# GD32E511_512 register map
File version: 1.0
CPU: CM33 r0p4, little endian, MPU, FPU, 4 interrupt priority bits
Registers are 32-bit, read-write, reset 0x0 unless marked. A register's access mark holds for its fields unless they carry their own. Offsets are from the block's base; [hi:lo] are bit positions.

## MDIO — Management data input/output
Base 0x4000D800
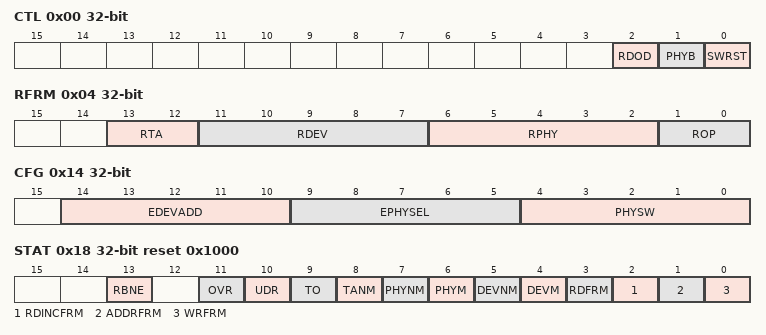
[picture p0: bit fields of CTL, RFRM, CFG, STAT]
0x00 CTL access per field — Control register
  [2] RDOD rw — receive data overrun disable
  [1] PHYB rw — MDIO PHY bit length
  [0] SWRST wo — Write 1 to reset MDIO block. Reisters will not be reset. Hardware immediately clears this bit.
0x04 RFRM ro — Received frame register
  [13:12] RTA — Received frame field TA (only accept TA bits of a write data frame or a write address frame)
  [11:7] RDEV — Received frame field DEVADD
  [6:2] RPHY — Received frame field PHYADR
  [1:0] ROP — Received frame field OP
0x08 RDATA ro — Received data register
  [15:0] RDATA — Received frame field DATA
0x0C RADDR ro — Received address register
  [15:0] RADDR — Received frame field ADDRESS
0x10 TDATA — Transfer data register
  [15:0] TDATA — Data that is transmitted by the next read or post read increment address frame. Before a read data frame, the master sends a write address frame to specify which data is to be read. After this write address frame, the user software must place this requested data into MDIO_TDATA before it is required by the read frame. The time available is at latest 3 MDIO clock cycles before TA.
0x14 CFG — Configuration register
  [14:10] EDEVADD — Expected DEVADD. Normally 01.
  [9:5] EPHYSEL — Selects expected PHYADR. For each x bit of the 5 bits:
  [4:0] PHYSW — Software provided PHYADR. Chosen according to corresponding EPHYSEL[4:0] bits
0x18 STAT ro reset 0x1000 — Status register
  [13] RBNE — Read data buffer not empty flag. Data is received and ready to be read. Cleared by reading the MDIO_RDATA register.
  [11] OVR — Receive overrun flag. Set by hardware when the data in the receive shift register is ready to be transferred into the MDIO_RDATA register while the RBNE bit is set. Cleared by reading the MDIO_RDATA register.
  [10] UDR — Transmit underrun flag. Set by hardware if the data has not been written to MDIO_TDATA register 3 MDIO clock cycles before TA of a read / post read increment address frame when the MDIO_TDATA is empty. Cleared by a write to the MDIO_TDATA register.
  [9] TO — Timeout flag. If a new bit of a frame is not received or a bit of the prepared data is not transmitted before reaching the configured timeout value, this bit will be set by hardware. Cleared by reading the MDIO_STAT register.
  [8] TANM — When the received TA is not 10 for a write data / address frame, this bit will be set at end bit of TA. Cleared by reading the MDIO_STAT register.
  [7] PHYNM — When the received PHYADR does not match, this bit will be set at end bit of PHYADR. Cleared by reading the MDIO_STAT register.
  [6] PHYM — When the received PHYADR matches, this bit will be set at end bit of PHYADR. Cleared by reading the MDIO_STAT register.
  [5] DEVNM — When the received DEVADD does not match, this bit will be set at end bit of DEVADD. Cleared by reading the MDIO_STAT register.
  [4] DEVM — When the received DEVADD matches, this bit will be set at end bit of DEVADD. Cleared by reading the MDIO_STAT register.
  [3] RDFRM — When the received DEVADD and PHYADR both match for a read data frame, this bit will be set at end bit (after frame field DATA transmission). Cleared by reading the MDIO_STAT register.
  [2] RDINCFRM — When the received DEVADD and PHYADR both match for a post read increment address frame, this bit will be set at end bit (after frame field DATA transmission). Cleared by reading MDIO_STAT register.
  [1] ADDRFRM — When the received DEVADD and PHYADR both match for a write address frame, this bit will be set at end bit (after frame field DATA transmission). Cleared by reading the MDIO_STAT register.
  [0] WRFRM — When the received DEVADD and PHYADR both match for a write data frame, this bit will be set at end bit (after frame field DATA transmission). Cleared by reading the MDIO_STAT register.
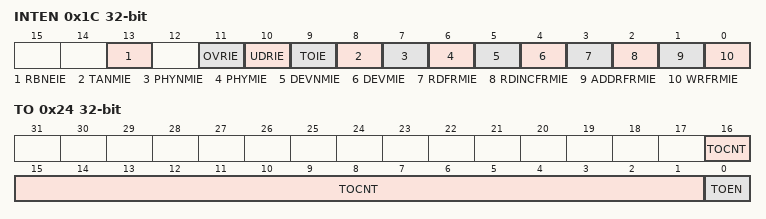
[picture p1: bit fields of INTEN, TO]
0x1C INTEN — Interrupt enable register
  [13] RBNEIE — An interrupt is generated when this bit and RBNE bit in MDIO_STAT register are both set.
  [11] OVRIE — An interrupt is generated when this bit and OVR bit in MDIO_STAT register are both set.
  [10] UDRIE — An interrupt is generated when this bit and UDR bit in MDIO_STAT register are both set.
  [9] TOIE — An interrupt is generated when this bit and TO bit in MDIO_STAT register are both set.
  [8] TANMIE — An interrupt is generated when this bit and TANM bit in MDIO_STAT register are both set.
  [7] PHYNMIE — An interrupt is generated when this bit and PHYNM bit in MDIO_STAT register are both set.
  [6] PHYMIE — An interrupt is generated when this bit and PHYM bit in MDIO_STAT register are both set.
  [5] DEVNMIE — An interrupt is generated when this bit and DEVNM bit in MDIO_STAT register are both set.
  [4] DEVMIE — An interrupt is generated when this bit and DEVM bit in MDIO_STAT register are both set.
  [3] RDFRMIE — An interrupt is generated when this bit and RDFRM bit in MDIO_STAT register are both set.
  [2] RDINCFRMIE — An interrupt is generated when this bit and RDINCFRM bit in MDIO_STAT register are both set.
  [1] ADDRFRMIE — An interrupt is generated when this bit and ADDRFRM bit in MDIO_STAT register are both set.
  [0] WRFRMIE — An interrupt is generated when this bit and WRFRM bit in MDIO_STAT register are both set.
0x20 PIN ro — Pin value register
  [4:0] PHYPIN — Pin value read from hardware MDIO_Ax pins
0x24 TO — Timeout register
  [16:1] TOCNT — MDIO time out = TOCNT[15:0]*PCLK
  [0] TOEN — Timeout enable
